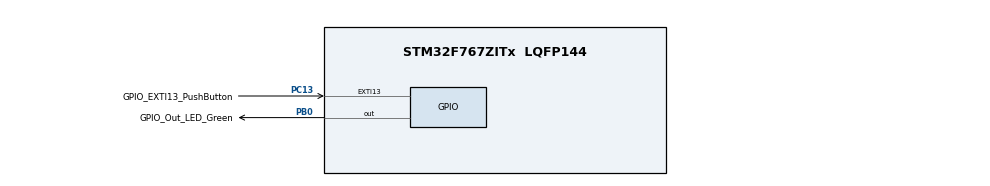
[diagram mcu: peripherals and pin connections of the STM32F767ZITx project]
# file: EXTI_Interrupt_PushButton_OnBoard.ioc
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Mcu.Family=STM32F7
Mcu.Name=STM32F767ZITx
Mcu.Package=LQFP144
NVIC.EXTI15_10_IRQn=true\:0\:0\:false\:false\:true\:true\:true\:true
NVIC.PriorityGroup=NVIC_PRIORITYGROUP_4
PA13.Mode=Serial_Wire
PA13.Signal=SYS_JTMS-SWDIO
PA14.Mode=Serial_Wire
PA14.Signal=SYS_JTCK-SWCLK
PB0.GPIO_Label=GPIO_Out_LED_Green
PB0.Signal=GPIO_Output
PC13.GPIO_Label=GPIO_EXTI13_PushButton
PC13.GPIO_ModeDefaultEXTI=GPIO_MODE_IT_FALLING
PC13.Signal=GPXTI13
ProjectManager.HeapSize=0x200
ProjectManager.StackSize=0x400
ProjectManager.TargetToolchain=CMake
RCC.HSE_VALUE=25000000
RCC.HSI_VALUE=16000000
RCC.LSE_VALUE=32768
RCC.USBFreq_Value=96000000
RCC.VCOOutputFreq_Value=192000000
board=custom

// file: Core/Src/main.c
/* USER CODE BEGIN Header */
/**
  ******************************************************************************
  * @file           : main.c
  * @brief          : Main program body
  ******************************************************************************
  * @author         : Jabed-Akhtar
  * @date           : 07.08.2022
  ******************************************************************************
  * @attention
  * - User Push-Button: PC13 (On-Board)
  * - LED: PB0(Green) (for testing purpose)
  * Description:
  *     - On pressing Button (PC13), LED (Green | PB0) toggles.
  *
  ******************************************************************************
  */
/* USER CODE END Header */
#include "main.h"

void SystemClock_Config(void);
static void MX_GPIO_Init(void);

int main(void)
{

  /* MCU Configuration--------------------------------------------------------*/

  /* Reset of all peripherals, Initializes the Flash interface and the Systick. */
  HAL_Init();

  /* Configure the system clock */
  SystemClock_Config();

  /* Initialize all configured peripherals */
  MX_GPIO_Init();

  /* Infinite loop */
  /* USER CODE BEGIN WHILE */
  while (1)
  {
  	__WFI(); // Wait for Interrupt -> Sleep-Mode
    /* USER CODE END WHILE */

  }
}

void SystemClock_Config(void)
{
  RCC_OscInitTypeDef RCC_OscInitStruct = {0};
  RCC_ClkInitTypeDef RCC_ClkInitStruct = {0};

  /** Configure the main internal regulator output voltage
  */
  __HAL_RCC_PWR_CLK_ENABLE();
  __HAL_PWR_VOLTAGESCALING_CONFIG(PWR_REGULATOR_VOLTAGE_SCALE3);

  /** Initializes the RCC Oscillators according to the specified parameters
  * in the RCC_OscInitTypeDef structure.
  */
  RCC_OscInitStruct.OscillatorType = RCC_OSCILLATORTYPE_HSI;
  RCC_OscInitStruct.HSIState = RCC_HSI_ON;
  RCC_OscInitStruct.HSICalibrationValue = RCC_HSICALIBRATION_DEFAULT;
  RCC_OscInitStruct.PLL.PLLState = RCC_PLL_NONE;
  if (HAL_RCC_OscConfig(&RCC_OscInitStruct) != HAL_OK)
  {
    Error_Handler();
  }

  /** Initializes the CPU, AHB and APB buses clocks
  */
  RCC_ClkInitStruct.ClockType = RCC_CLOCKTYPE_HCLK|RCC_CLOCKTYPE_SYSCLK
                              |RCC_CLOCKTYPE_PCLK1|RCC_CLOCKTYPE_PCLK2;
  RCC_ClkInitStruct.SYSCLKSource = RCC_SYSCLKSOURCE_HSI;
  RCC_ClkInitStruct.AHBCLKDivider = RCC_SYSCLK_DIV1;
  RCC_ClkInitStruct.APB1CLKDivider = RCC_HCLK_DIV1;
  RCC_ClkInitStruct.APB2CLKDivider = RCC_HCLK_DIV1;

  if (HAL_RCC_ClockConfig(&RCC_ClkInitStruct, FLASH_LATENCY_0) != HAL_OK)
  {
    Error_Handler();
  }
}

static void MX_GPIO_Init(void)
{
  GPIO_InitTypeDef GPIO_InitStruct = {0};

  /* GPIO Ports Clock Enable */
  __HAL_RCC_GPIOC_CLK_ENABLE();
  __HAL_RCC_GPIOB_CLK_ENABLE();
  __HAL_RCC_GPIOA_CLK_ENABLE();

  /*Configure GPIO pin Output Level */
  HAL_GPIO_WritePin(GPIO_Out_LED_Green_GPIO_Port, GPIO_Out_LED_Green_Pin, GPIO_PIN_RESET);

  /*Configure GPIO pin : GPIO_EXTI13_PushButton_Pin */
  GPIO_InitStruct.Pin = GPIO_EXTI13_PushButton_Pin;
  GPIO_InitStruct.Mode = GPIO_MODE_IT_FALLING;
  GPIO_InitStruct.Pull = GPIO_NOPULL;
  HAL_GPIO_Init(GPIO_EXTI13_PushButton_GPIO_Port, &GPIO_InitStruct);

  /*Configure GPIO pin : GPIO_Out_LED_Green_Pin */
  GPIO_InitStruct.Pin = GPIO_Out_LED_Green_Pin;
  GPIO_InitStruct.Mode = GPIO_MODE_OUTPUT_PP;
  GPIO_InitStruct.Pull = GPIO_NOPULL;
  GPIO_InitStruct.Speed = GPIO_SPEED_FREQ_LOW;
  HAL_GPIO_Init(GPIO_Out_LED_Green_GPIO_Port, &GPIO_InitStruct);

  /* EXTI interrupt init*/
  HAL_NVIC_SetPriority(EXTI15_10_IRQn, 0, 0);
  HAL_NVIC_EnableIRQ(EXTI15_10_IRQn);

}

void Error_Handler(void)
{
  __disable_irq();
  while (1)
  {
  }
}
